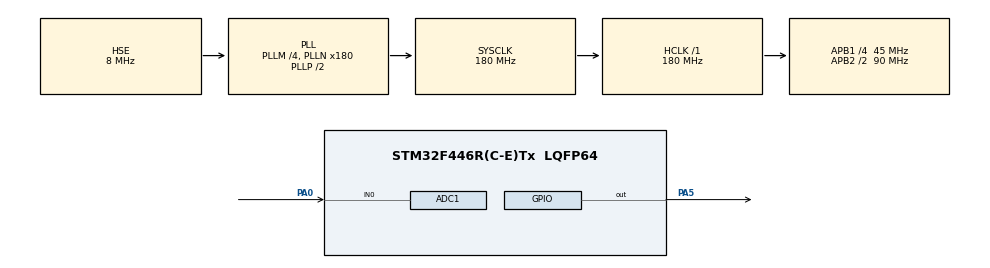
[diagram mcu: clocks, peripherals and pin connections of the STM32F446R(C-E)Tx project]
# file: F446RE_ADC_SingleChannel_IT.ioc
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ADC1.Channel-0\#ChannelRegularConversion=ADC_CHANNEL_0
ADC1.ContinuousConvMode=ENABLE
ADC1.NbrOfConversionFlag=1
ADC1.Rank-0\#ChannelRegularConversion=1
ADC1.SamplingTime-0\#ChannelRegularConversion=ADC_SAMPLETIME_480CYCLES
ADC1.master=1
Mcu.Family=STM32F4
Mcu.Name=STM32F446R(C-E)Tx
Mcu.Package=LQFP64
NVIC.ADC_IRQn=true\:0\:0\:false\:false\:true\:true\:true\:true
NVIC.PriorityGroup=NVIC_PRIORITYGROUP_4
PA0-WKUP.Signal=ADCx_IN0
PA13.Mode=Serial_Wire
PA13.Signal=SYS_JTMS-SWDIO
PA14.Mode=Serial_Wire
PA14.Signal=SYS_JTCK-SWCLK
PA5.Signal=GPIO_Output
PH0-OSC_IN.Mode=HSE-External-Clock-Source
PH0-OSC_IN.Signal=RCC_OSC_IN
PH1-OSC_OUT.Mode=HSE-External-Clock-Source
PH1-OSC_OUT.Signal=RCC_OSC_OUT
ProjectManager.HeapSize=0x200
ProjectManager.StackSize=0x400
ProjectManager.TargetToolchain=STM32CubeIDE
RCC.AHBFreq_Value=180000000
RCC.APB1CLKDivider=RCC_HCLK_DIV4
RCC.APB1Freq_Value=45000000
RCC.APB1TimFreq_Value=90000000
RCC.APB2CLKDivider=RCC_HCLK_DIV2
RCC.APB2Freq_Value=90000000
RCC.APB2TimFreq_Value=180000000
RCC.CortexFreq_Value=180000000
RCC.HCLKFreq_Value=180000000
RCC.HSE_VALUE=8000000
RCC.PLLM=4
RCC.PLLN=180
RCC.PLLSourceVirtual=RCC_PLLSOURCE_HSE
RCC.SYSCLKFreq_VALUE=180000000
RCC.SYSCLKSource=RCC_SYSCLKSOURCE_PLLCLK
RCC.USBFreq_Value=180000000
RCC.VCOOutputFreq_Value=360000000
SH.ADCx_IN0.0=ADC1_IN0,IN0
board=custom

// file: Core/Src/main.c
/* USER CODE BEGIN Header */
/**
  ******************************************************************************
  * @file           : main.c
  * @brief          : Main program body
  ******************************************************************************
  * @attention
  *
  * Copyright (c) 2026 STMicroelectronics.
  * All rights reserved.
  *
  * This software is licensed under terms that can be found in the LICENSE file
  * in the root directory of this software component.
  * If no LICENSE file comes with this software, it is provided AS-IS.
  *
  ******************************************************************************
  */
/* USER CODE END Header */
#include "main.h"

ADC_HandleTypeDef hadc1;

void SystemClock_Config(void);
static void MX_GPIO_Init(void);
static void MX_ADC1_Init(void);

/* USER CODE BEGIN 0 */

	//ADC_Clock_Frequency = Internal_Bus_Peripheral_Clock_Freq / ADC_Prescaler
	//ADC_Conversion_Time = (Sampling_Cycles + Conversion_Cycles) / ADC_Clock_Frequency
	//ADC_Sampling_Rate = 1/ADC_Conversion_Time

	//eg: ADC1 connected to APB1, let APB1 peripheral clock = 4 Mhz and ADC_Prescaler = 6
	//	  ADC_Clock_Freq = 666.67 kHz
	//	  Sampling_Cycles is selected in the ADC setting, min 3
	//	  Conversion_Cycles depends on MCU and ADC resolution, for F446RE, 12bit ADC requires 12 cycles
	//	  let Sampling_Cycles = 480, and 12bit ADC, then ADC_Conversion_Time = 492/666.67kHz = 738 us
	//	  ADC_Sampling_Rate = 1/738us = 1353 samples per seconds

uint16_t ADC_VAL = 0;	//we're using 12 bit ADC, we need atleast 16bit to store the raw ADC value [0–4095]
int scaledValue = 0;	//maps the raw ADC value to more convenient value eg [0-100]
int count=0;

//function to map the raw ADC values to scaled values, long has bigger range than int
long map(long x, long in_min, long in_max, long out_min, long out_max)
{
  return (x - in_min) * (out_max - out_min + 1) / (in_max - in_min + 1) + out_min;
}

	//in ADC Interrupt, the adc will execute the conversion in the background and trigger "Conversion Complete" Interrupt.
	//Then conversion complete callback function will be called. CPU only steps in to read the result during the interrupt.
	//In continuous conversion mode, the adc will restart automatically after the previous conversion is complete

void HAL_ADC_ConvCpltCallback(ADC_HandleTypeDef *hadc)
{
	//we can process the data in this callback function
	ADC_VAL = HAL_ADC_GetValue(&hadc1);
	scaledValue = map(ADC_VAL, 0, 4095, 0, 100);
	count++;
}

/* USER CODE END 0 */

int main(void)
{

  /* MCU Configuration--------------------------------------------------------*/

  /* Reset of all peripherals, Initializes the Flash interface and the Systick. */
  HAL_Init();

  /* Configure the system clock */
  SystemClock_Config();

  /* Initialize all configured peripherals */
  MX_GPIO_Init();
  MX_ADC1_Init();
  /* USER CODE BEGIN 2 */

//Dont set the ADC clock too high. If the conversion time is very low, the interrupts will
//trigger at an extremely high rate and this will make the while loop unusable. Tradeoff
//between the sampling rate and the while loop

  HAL_ADC_Start_IT(&hadc1);	//run outside of while loop because continous conv is enabled

  /* USER CODE END 2 */

  /* Infinite loop */
  while (1)
  {

    /* USER CODE BEGIN 3 */

	  HAL_GPIO_TogglePin(GPIOA, GPIO_PIN_5);
      HAL_Delay(500);	//500ms delay, manually sets the ADC to run at 2Hz

  }
  /* USER CODE END 3 */
}

void SystemClock_Config(void)
{
  RCC_OscInitTypeDef RCC_OscInitStruct = {0};
  RCC_ClkInitTypeDef RCC_ClkInitStruct = {0};

  /** Configure the main internal regulator output voltage
  */
  __HAL_RCC_PWR_CLK_ENABLE();
  __HAL_PWR_VOLTAGESCALING_CONFIG(PWR_REGULATOR_VOLTAGE_SCALE1);

  /** Initializes the RCC Oscillators according to the specified parameters
  * in the RCC_OscInitTypeDef structure.
  */
  RCC_OscInitStruct.OscillatorType = RCC_OSCILLATORTYPE_HSE;
  RCC_OscInitStruct.HSEState = RCC_HSE_BYPASS;
  RCC_OscInitStruct.PLL.PLLState = RCC_PLL_ON;
  RCC_OscInitStruct.PLL.PLLSource = RCC_PLLSOURCE_HSE;
  RCC_OscInitStruct.PLL.PLLM = 4;
  RCC_OscInitStruct.PLL.PLLN = 180;
  RCC_OscInitStruct.PLL.PLLP = RCC_PLLP_DIV2;
  RCC_OscInitStruct.PLL.PLLQ = 2;
  RCC_OscInitStruct.PLL.PLLR = 2;
  if (HAL_RCC_OscConfig(&RCC_OscInitStruct) != HAL_OK)
  {
    Error_Handler();
  }

  /** Activate the Over-Drive mode
  */
  if (HAL_PWREx_EnableOverDrive() != HAL_OK)
  {
    Error_Handler();
  }

  /** Initializes the CPU, AHB and APB buses clocks
  */
  RCC_ClkInitStruct.ClockType = RCC_CLOCKTYPE_HCLK|RCC_CLOCKTYPE_SYSCLK
                              |RCC_CLOCKTYPE_PCLK1|RCC_CLOCKTYPE_PCLK2;
  RCC_ClkInitStruct.SYSCLKSource = RCC_SYSCLKSOURCE_PLLCLK;
  RCC_ClkInitStruct.AHBCLKDivider = RCC_SYSCLK_DIV1;
  RCC_ClkInitStruct.APB1CLKDivider = RCC_HCLK_DIV4;
  RCC_ClkInitStruct.APB2CLKDivider = RCC_HCLK_DIV2;

  if (HAL_RCC_ClockConfig(&RCC_ClkInitStruct, FLASH_LATENCY_5) != HAL_OK)
  {
    Error_Handler();
  }
}

static void MX_ADC1_Init(void)
{

  ADC_ChannelConfTypeDef sConfig = {0};

  /** Configure the global features of the ADC (Clock, Resolution, Data Alignment and number of conversion)
  */
  hadc1.Instance = ADC1;
  hadc1.Init.ClockPrescaler = ADC_CLOCK_SYNC_PCLK_DIV4;
  hadc1.Init.Resolution = ADC_RESOLUTION_12B;
  hadc1.Init.ScanConvMode = DISABLE;
  hadc1.Init.ContinuousConvMode = ENABLE;
  hadc1.Init.DiscontinuousConvMode = DISABLE;
  hadc1.Init.ExternalTrigConvEdge = ADC_EXTERNALTRIGCONVEDGE_NONE;
  hadc1.Init.ExternalTrigConv = ADC_SOFTWARE_START;
  hadc1.Init.DataAlign = ADC_DATAALIGN_RIGHT;
  hadc1.Init.NbrOfConversion = 1;
  hadc1.Init.DMAContinuousRequests = DISABLE;
  hadc1.Init.EOCSelection = ADC_EOC_SINGLE_CONV;
  if (HAL_ADC_Init(&hadc1) != HAL_OK)
  {
    Error_Handler();
  }

  /** Configure for the selected ADC regular channel its corresponding rank in the sequencer and its sample time.
  */
  sConfig.Channel = ADC_CHANNEL_0;
  sConfig.Rank = 1;
  sConfig.SamplingTime = ADC_SAMPLETIME_480CYCLES;
  if (HAL_ADC_ConfigChannel(&hadc1, &sConfig) != HAL_OK)
  {
    Error_Handler();
  }

}

static void MX_GPIO_Init(void)
{
  GPIO_InitTypeDef GPIO_InitStruct = {0};

  /* GPIO Ports Clock Enable */
  __HAL_RCC_GPIOH_CLK_ENABLE();
  __HAL_RCC_GPIOA_CLK_ENABLE();

  /*Configure GPIO pin Output Level */
  HAL_GPIO_WritePin(GPIOA, GPIO_PIN_5, GPIO_PIN_RESET);

  /*Configure GPIO pin : PA5 */
  GPIO_InitStruct.Pin = GPIO_PIN_5;
  GPIO_InitStruct.Mode = GPIO_MODE_OUTPUT_PP;
  GPIO_InitStruct.Pull = GPIO_NOPULL;
  GPIO_InitStruct.Speed = GPIO_SPEED_FREQ_LOW;
  HAL_GPIO_Init(GPIOA, &GPIO_InitStruct);

}

void Error_Handler(void)
{
  __disable_irq();
  while (1)
  {
  }
}
